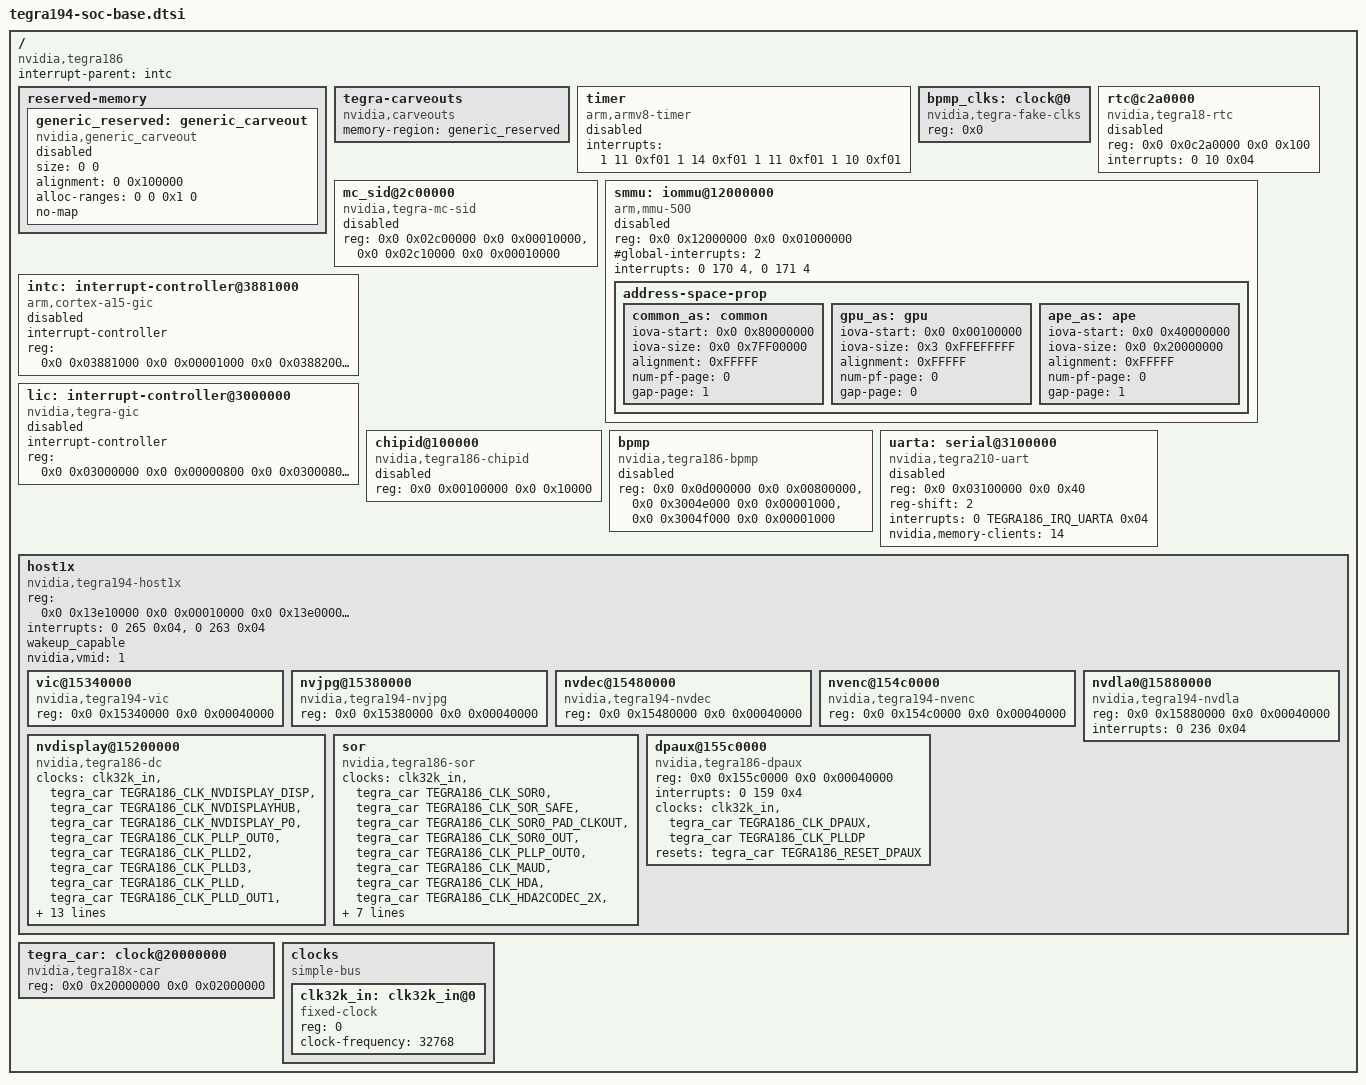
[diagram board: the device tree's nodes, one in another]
/*
 * tegra186-soc-base.dtsi: SoC Base DTSI file.
 *
 * Copyright (c) 2014-2016, NVIDIA CORPORATION.  All rights reserved.
 *
 * This program is free software; you can redistribute it and/or modify
 * it under the terms of the GNU General Public License as published by
 * the Free Software Foundation; version 2 of the License.
 *
 * This program is distributed in the hope that it will be useful, but WITHOUT
 * ANY WARRANTY; without even the implied warranty of MERCHANTABILITY or
 * FITNESS FOR A PARTICULAR PURPOSE.  See the GNU General Public License for
 * more details.
 *
 * You should have received a copy of the GNU General Public License along
 * with this program; if not, write to the Free Software Foundation, Inc.,
 * 51 Franklin Street, Fifth Floor, Boston, MA  02110-1301, USA.
 *
 */

#include <dt-bindings/clock/tegra194-clock.h>
#include "dt-bindings/display/tegra-dc.h"
#include "dt-bindings/interrupt/tegra186-irq.h"
#include "dt-bindings/clock/tegra186-clock.h"
#include "dt-bindings/reset/tegra186-reset.h"
#include "dt-bindings/soc/tegra186-powergate.h"

/ {
	compatible = "nvidia,tegra186";
	interrupt-parent = <&intc>;
	#address-cells = <2>;
	#size-cells = <2>;

	reserved-memory {
		#address-cells = <2>;
		#size-cells = <2>;
		ranges;

		generic_reserved: generic_carveout {
			compatible = "nvidia,generic_carveout";
			size = <0 0>;
			alignment = <0 0x100000>;
			alloc-ranges = <0 0 0x1 0>;
			no-map;
			status = "disabled";
		};
	};

	tegra-carveouts {
		compatible = "nvidia,carveouts";
		memory-region = <&generic_reserved>;
	};

	timer {
		compatible = "arm,armv8-timer";
		interrupts = <1 11 0xf01
			      1 14 0xf01
			      1 11 0xf01
			      1 10 0xf01>;
		status = "disabled";
	};

	bpmp_clks: clock@0 {
		compatible = "nvidia,tegra-fake-clks";
		reg = <0x0>;
		#clock-cells = <1>;
		status = "okay";
	};

	rtc@c2a0000 {
		compatible = "nvidia,tegra18-rtc";
		reg = <0x0 0x0c2a0000 0x0 0x100>;
		interrupts = <0 10 0x04>;
		status = "disabled";
	};

	mc_sid@2c00000 {
		compatible = "nvidia,tegra-mc-sid";
 		reg = <0x0 0x02c00000 0x0 0x00010000>, /* MC_SID_BASE */
 		      <0x0 0x02c10000 0x0 0x00010000>; /* MC_BASE */
		status = "disabled";
	};

	/* HACK: Populate earlier than other device */
	smmu: iommu@12000000{
		compatible = "arm,mmu-500";
		reg = <0x0 0x12000000 0x0 0x01000000>; /* 16MB */
		#global-interrupts = <2>;
		interrupts = <0 170 4>,
			     <0 171 4>;
		status = "disabled";

		address-space-prop {
			common_as: common {
				iova-start = <0x0 0x80000000>;
				iova-size = <0x0 0x7FF00000>;
				alignment = <0xFFFFF>;
				num-pf-page = <0>;
				gap-page = <1>;
			};
			gpu_as: gpu {
				iova-start = <0x0 0x00100000>;
				iova-size = <0x3 0xFFEFFFFF>;
				alignment = <0xFFFFF>;
				num-pf-page = <0>;
				gap-page = <0>;
			};
			ape_as: ape {
				iova-start = <0x0 0x40000000>;
				iova-size = <0x0 0x20000000>;
				alignment = <0xFFFFF>;
				num-pf-page = <0>;
				gap-page = <1>;
			};
		};
	};


	intc: interrupt-controller@3881000 {
		compatible = "arm,cortex-a15-gic";
		#interrupt-cells = <3>;
		interrupt-controller;
		reg = <0x0 0x03881000 0x0 0x00001000
		       0x0 0x03882000 0x0 0x00002000>;
		status = "disabled";
	};

	lic: interrupt-controller@3000000 {
		compatible = "nvidia,tegra-gic";
		interrupt-controller;
		reg = <0x0 0x03000000 0x0 0x00000800
			0x0 0x03000800 0x0 0x00000800
			0x0 0x03001000 0x0 0x00000800
			0x0 0x03001800 0x0 0x00000800
			0x0 0x03002000 0x0 0x00000800
			0x0 0x03002800 0x0 0x00000800
			0x0 0x03003000 0x0 0x00000800
			0x0 0x03003800 0x0 0x00000800
			0x0 0x0300f800 0x0 0x00000800>;
		status = "disabled";
	};

	chipid@100000 {
		compatible = "nvidia,tegra186-chipid";
		reg = <0x0 0x00100000 0x0 0x10000>;
		status = "disabled";
	};

	bpmp {
		compatible = "nvidia,tegra186-bpmp";
		#stream-id-cells = <1>;
		reg = <0x0 0x0d000000 0x0 0x00800000>,
		      <0x0 0x3004e000 0x0 0x00001000>,
		      <0x0 0x3004f000 0x0 0x00001000>;
		status = "disabled";
	};

	uarta: serial@3100000 {
		compatible = "nvidia,tegra210-uart";
		#stream-id-cells = <1>;
		reg = <0x0 0x03100000 0x0 0x40>;
		reg-shift = <2>;
		interrupts = <0 TEGRA186_IRQ_UARTA 0x04>;
		nvidia,memory-clients = <14>;
		dma-names = "rx", "tx";
		clock-names = "serial", "parent";
		reset-names = "serial";
		status = "disabled";
	};

	host1x: host1x {
		compatible = "nvidia,tegra194-host1x", "simple-bus";
		reg = <0x0 0x13e10000 0x0 0x00010000
		       0x0 0x13e00000 0x0 0x00010000
		       0x0 0x13ec0000 0x0 0x00040000>;
		interrupts = <0 265 0x04>,
			     <0 263 0x04>;

		wakeup_capable;

		nvidia,vmid = <1>;

		#stream-id-cells = <9>;
		#address-cells = <2>;
		#size-cells = <2>;

		ranges;

		vic@15340000 {
			compatible = "nvidia,tegra194-vic";
			reg = <0x0 0x15340000 0x0 0x00040000>;

			#stream-id-cells = <1>;
		};

		nvjpg@15380000 {
			compatible = "nvidia,tegra194-nvjpg";
			reg = <0x0 0x15380000 0x0 0x00040000>;

			#stream-id-cells = <1>;
		};

		nvdec@15480000 {
			compatible = "nvidia,tegra194-nvdec";
			reg = <0x0 0x15480000 0x0 0x00040000>;

			#stream-id-cells = <1>;
		};

		nvenc@154c0000 {
			compatible = "nvidia,tegra194-nvenc";
			reg = <0x0 0x154c0000 0x0 0x00040000>;

			#stream-id-cells = <1>;
		};

		nvdla0@15880000 {
			compatible = "nvidia,tegra194-nvdla";
			reg = <0x0 0x15880000 0x0 0x00040000>;
			interrupts = <0 236 0x04>;

			#stream-id-cells = <1>;
		};

		nvdisplay@15200000 {
			clock-names = "clk32k_in", "nvdisplay_disp",
				      "nvdisplayhub", "nvdisplay_p0",
				      "pllp_display", "plld2", "plld3",
				      "pll_d", "pll_d_out1", "emc", "emc_latency";
			clocks = <&clk32k_in>,
				 <&tegra_car TEGRA186_CLK_NVDISPLAY_DISP>,
				 <&tegra_car TEGRA186_CLK_NVDISPLAYHUB>,
				 <&tegra_car TEGRA186_CLK_NVDISPLAY_P0>,
				 <&tegra_car TEGRA186_CLK_PLLP_OUT0>,
				 <&tegra_car TEGRA186_CLK_PLLD2>,
				 <&tegra_car TEGRA186_CLK_PLLD3>,
				 <&tegra_car TEGRA186_CLK_PLLD>,
				 <&tegra_car TEGRA186_CLK_PLLD_OUT1>,
				 <&tegra_car TEGRA186_CLK_EMC>,
				 <&tegra_car TEGRA186_CLK_CLK_M>;
			compatible = "nvidia,tegra186-dc";
			reg = <0x0 0x15200000 0x0 0x10000>;
			interrupts = <0x0 0x99 0x4>;

			#stream-id-cells = <0x1>;
			reset-names = "misc", "wgrp0", "wgrp1", "wgrp2",
				      "wgrp3", "wgrp4", "wgrp5", "head0";
			resets = <&tegra_car TEGRA186_RESET_NVDISPLAY0_MISC>,
				 <&tegra_car TEGRA186_RESET_NVDISPLAY0_WGRP0>,
				 <&tegra_car TEGRA186_RESET_NVDISPLAY0_WGRP1>,
				 <&tegra_car TEGRA186_RESET_NVDISPLAY0_WGRP2>,
				 <&tegra_car TEGRA186_RESET_NVDISPLAY0_WGRP3>,
				 <&tegra_car TEGRA186_RESET_NVDISPLAY0_WGRP4>,
				 <&tegra_car TEGRA186_RESET_NVDISPLAY0_WGRP5>,
				 <&tegra_car TEGRA186_RESET_NVDISPLAY0_HEAD0>;
		}; //nvdisplay@15200000

		sor {
			clocks = <&clk32k_in>,
				 <&tegra_car TEGRA186_CLK_SOR0>,
				 <&tegra_car TEGRA186_CLK_SOR_SAFE>,
				 <&tegra_car TEGRA186_CLK_SOR0_PAD_CLKOUT>,
				 <&tegra_car TEGRA186_CLK_SOR0_OUT>,
				 <&tegra_car TEGRA186_CLK_PLLP_OUT0>,
				 <&tegra_car TEGRA186_CLK_MAUD>,
				 <&tegra_car TEGRA186_CLK_HDA>,
				 <&tegra_car TEGRA186_CLK_HDA2CODEC_2X>,
				 <&tegra_car TEGRA186_CLK_HDA2HDMICODEC>;
			clock-names = "clk32k_in", "sor0", "sor_safe",
				      "sor0_pad_clkout", "sor0_out",
				      "pllp_out0", "maud", "hda",
				      "hda2codec_2x", "hda2hdmi";
			compatible = "nvidia,tegra186-sor";
			nvidia,xbar-ctrl = <0x2 0x1 0x0 0x3 0x4>;
			reg = <0x0 0x15540000 0x0 0x40000>;
			resets = <&tegra_car TEGRA186_RESET_SOR0>,
				 <&tegra_car TEGRA186_RESET_HDA>,
				 <&tegra_car TEGRA186_RESET_HDA2CODEC_2X>,
				 <&tegra_car TEGRA186_RESET_HDA2HDMICODEC>;
			reset-names = "sor0","hda_rst", "hda2codec_2x_rst",
				"hda2hdmi_rst";
		}; //sor

		dpaux@155c0000 {
			compatible = "nvidia,tegra186-dpaux";
			reg = <0x0 0x155c0000 0x0 0x00040000>;
			interrupts = <0 159 0x4>; // INT_DPAUX
			clocks = <&clk32k_in>,
				 <&tegra_car TEGRA186_CLK_DPAUX>,
				 <&tegra_car TEGRA186_CLK_PLLDP>;
			clock-names = "clk32k_in", "dpaux", "plldp";
			resets = <&tegra_car TEGRA186_RESET_DPAUX>;
			reset-names = "dpaux";
		}; //dpaux@155c0000

	}; // host1x

	tegra_car: clock@20000000 {
		compatible = "nvidia,tegra18x-car";
		reg = <0x0 0x20000000 0x0 0x02000000>;
		#clock-cells = <1>;
		#reset-cells = <1>;
	};

	clocks {
		compatible = "simple-bus";
		#address-cells = <1>;
		#size-cells = <0>;

		clk32k_in: clk32k_in@0 {
			compatible = "fixed-clock";
			reg = <0>;
			#clock-cells = <0>;
			clock-frequency = <32768>;
			status = "okay";
		};
	};
};
